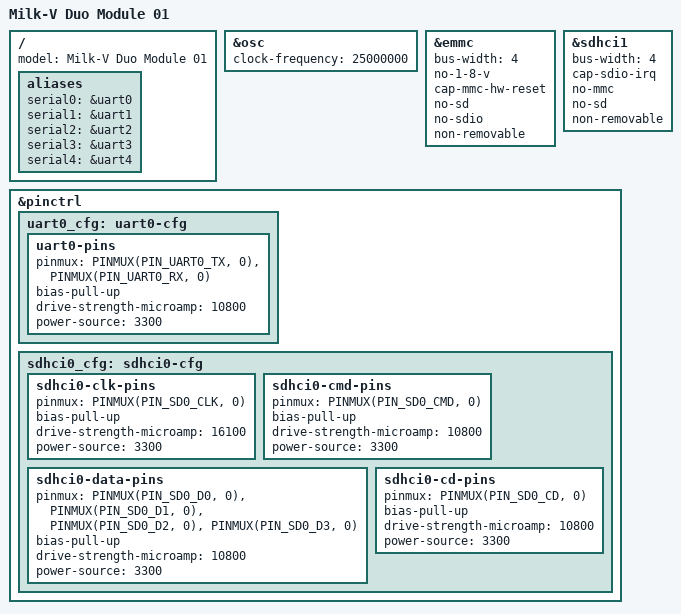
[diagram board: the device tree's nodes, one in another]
// SPDX-License-Identifier: (GPL-2.0 OR MIT)

#include <dt-bindings/pinctrl/pinctrl-sg2000.h>
#include "sg2000.dtsi"

/ {
	model = "Milk-V Duo Module 01";

	aliases {
		serial0 = &uart0;
		serial1 = &uart1;
		serial2 = &uart2;
		serial3 = &uart3;
		serial4 = &uart4;
	};
};

&osc {
	clock-frequency = <25000000>;
};

&emmc {
	/delete-property/ status;
	bus-width = <4>;
	no-1-8-v;
	cap-mmc-hw-reset;
	no-sd;
	no-sdio;
	non-removable;
};

/* Wi-Fi */
&sdhci1 {
	bus-width = <4>;
	cap-sdio-irq;
	no-mmc;
	no-sd;
	non-removable;
};

&pinctrl {
	uart0_cfg: uart0-cfg {
		uart0-pins {
			pinmux = <PINMUX(PIN_UART0_TX, 0)>,
				 <PINMUX(PIN_UART0_RX, 0)>;
			bias-pull-up;
			drive-strength-microamp = <10800>;
			power-source = <3300>;
		};
	};

	sdhci0_cfg: sdhci0-cfg {
		sdhci0-clk-pins {
			pinmux = <PINMUX(PIN_SD0_CLK, 0)>;
			bias-pull-up;
			drive-strength-microamp = <16100>;
			power-source = <3300>;
		};

		sdhci0-cmd-pins {
			pinmux = <PINMUX(PIN_SD0_CMD, 0)>;
			bias-pull-up;
			drive-strength-microamp = <10800>;
			power-source = <3300>;
		};

		sdhci0-data-pins {
			pinmux = <PINMUX(PIN_SD0_D0, 0)>,
				 <PINMUX(PIN_SD0_D1, 0)>,
				 <PINMUX(PIN_SD0_D2, 0)>,
				 <PINMUX(PIN_SD0_D3, 0)>;
			bias-pull-up;
			drive-strength-microamp = <10800>;
			power-source = <3300>;
		};

		sdhci0-cd-pins {
			pinmux = <PINMUX(PIN_SD0_CD, 0)>;
			bias-pull-up;
			drive-strength-microamp = <10800>;
			power-source = <3300>;
		};
	};
};
